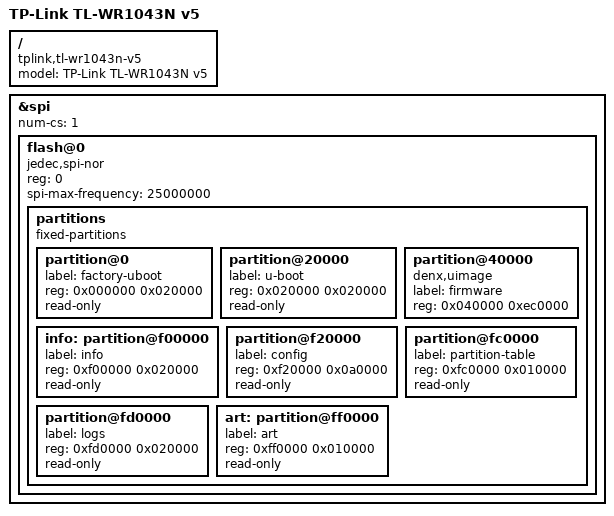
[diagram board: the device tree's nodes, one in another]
// SPDX-License-Identifier: GPL-2.0-or-later OR MIT

#include "qca9563_tplink_tl-wr1043n.dtsi"

/ {
	compatible = "tplink,tl-wr1043n-v5", "qca,qca9563";
	model = "TP-Link TL-WR1043N v5";
};

&spi {
	status = "okay";
	num-cs = <1>;

	flash@0 {
		compatible = "jedec,spi-nor";
		reg = <0>;
		spi-max-frequency = <25000000>;

		partitions {
			compatible = "fixed-partitions";
			#address-cells = <1>;
			#size-cells = <1>;

			partition@0 {
				label = "factory-uboot";
				reg = <0x000000 0x020000>;
				read-only;
			};

			partition@20000 {
				label = "u-boot";
				reg = <0x020000 0x020000>;
				read-only;
			};

			partition@40000 {
				compatible = "denx,uimage";
				label = "firmware";
				reg = <0x040000 0xec0000>;
			};

			info: partition@f00000 {
				label = "info";
				reg = <0xf00000 0x020000>;
				read-only;
			};

			partition@f20000 {
				label = "config";
				reg = <0xf20000 0x0a0000>;
				read-only;
			};

			partition@fc0000 {
				label = "partition-table";
				reg = <0xfc0000 0x010000>;
				read-only;
			};

			partition@fd0000 {
				label = "logs";
				reg = <0xfd0000 0x020000>;
				read-only;
			};

			art: partition@ff0000 {
				label = "art";
				reg = <0xff0000 0x010000>;
				read-only;
			};
		};
	};
};
